AUTOSAR XML (schema 4-3-0)
package /cdd_rfic
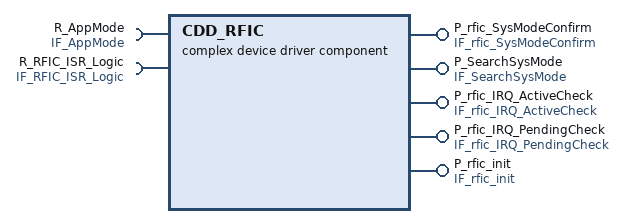
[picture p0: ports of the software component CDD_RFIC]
  complex device driver sw component type CDD_RFIC
    5 x provide port:
      P_rfic_SysModeConfirm: nonqueued-sender-com-spec=SR, provided-interface=IF_rfic_SysModeConfirm
      P_SearchSysMode: server-com-spec{operation=CS, queue-length=1}, provided-interface=IF_SearchSysMode
      P_rfic_IRQ_ActiveCheck: server-com-spec{operation=CS, queue-length=1}, provided-interface=IF_rfic_IRQ_ActiveCheck
      P_rfic_IRQ_PendingCheck: server-com-spec{operation=CS, queue-length=1}, provided-interface=IF_rfic_IRQ_PendingCheck
      P_rfic_init: server-com-spec{operation=CS, queue-length=1}, provided-interface=IF_rfic_init
    require port R_AppMode: required-com-specs=[AppActive, AppSleep], required-interface=IF_AppMode
    require port R_RFIC_ISR_Logic: client-com-spec=CS, required-interface=IF_RFIC_ISR_Logic
    behavior InternalBehavior
      4 x operation invoked event:
        OIE_RE_SearchSysmode_P_SearchSysMode_CS: start-on-event=RE_SearchSysmode, operation=P_SearchSysMode.CS
        OIE_RE_rfic_IRQ_ActiveCheck_P_rfic_IRQ_ActiveCheck_CS: start-on-event=RE_rfic_IRQ_ActiveCheck, operation=P_rfic_IRQ_ActiveCheck.CS
        OIE_RE_rfic_IRQ_PendingCheck_P_rfic_IRQ_PendingCheck_CS: start-on-event=RE_rfic_IRQ_PendingCheck, operation=P_rfic_IRQ_PendingCheck.CS
        OIE_RE_rfic_init_P_rfic_init_CS: start-on-event=RE_rfic_init, operation=P_rfic_init.CS
      5 x runnable, all with can-be-invoked-concurrently=true:
        RE_SearchSysmode
        RE_rfic_IRQ_ActiveCheck
        RE_rfic_IRQ_PendingCheck
        RE_rfic_init
        RE_TPMS_RF_Failure_Status
  swc implementation CDD_RFIC_Implementation: behavior=InternalBehavior
